# f28e12x_mem_cfg_regs register map
Vendor: Texas Instruments
Peripheral module from a debugger description file (folder C2000).
Address unit: 16 bits
Registers are 32-bit, read-write, no defined reset value unless marked. A register's access mark holds for its fields unless they carry their own. Offsets are as the file gives them; lines under a group give offsets from that group; [hi:lo] are bit positions; {n}, {i} and the like mark numbered series; 'fields as' and 'values as' point back to an identical list; <NAME> marks a mode.

## MEM_CFG_REGS — MEM CFG Registers
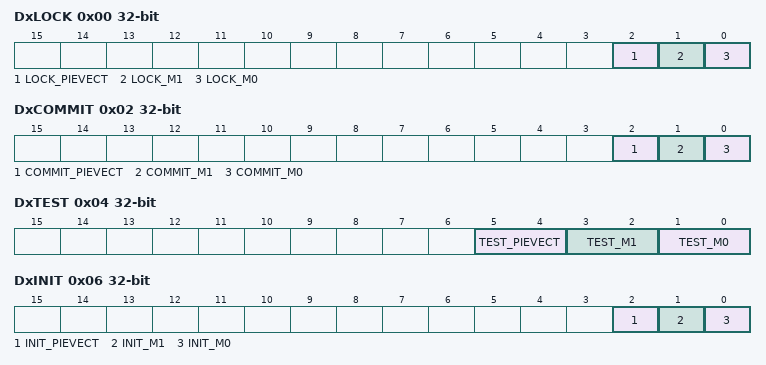
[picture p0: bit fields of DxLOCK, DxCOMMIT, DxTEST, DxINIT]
0x00 DxLOCK — Dedicated RAM config Lock Register
  [2] LOCK_PIEVECT — PIEVECT RAM Lock bits
  [1] LOCK_M1 — M1 RAM Lock bits
  [0] LOCK_M0 — M0 RAM Lock bits
0x02 DxCOMMIT — Dedicated RAM config Lock Commit Register
  [2] COMMIT_PIEVECT — PIEVECT RAM Permanent Lock bits
  [1] COMMIT_M1 — M1 RAM Permanent Lock bits
  [0] COMMIT_M0 — M0 RAM Permanent Lock bits
0x04 DxTEST — Dedicated RAM TEST Register
  [5:4] TEST_PIEVECT — Selects the different modes for PIEVECT RAM
  [3:2] TEST_M1 — Selects the different modes for M1 RAM
  [1:0] TEST_M0 — Selects the different modes for M0 RAM
0x06 DxINIT — Dedicated RAM Init Register
  [2] INIT_PIEVECT — RAM Initialization control for PIEVECT RAM.
  [1] INIT_M1 — RAM Initialization control for M1 RAM.
  [0] INIT_M0 — RAM Initialization control for M0 RAM.
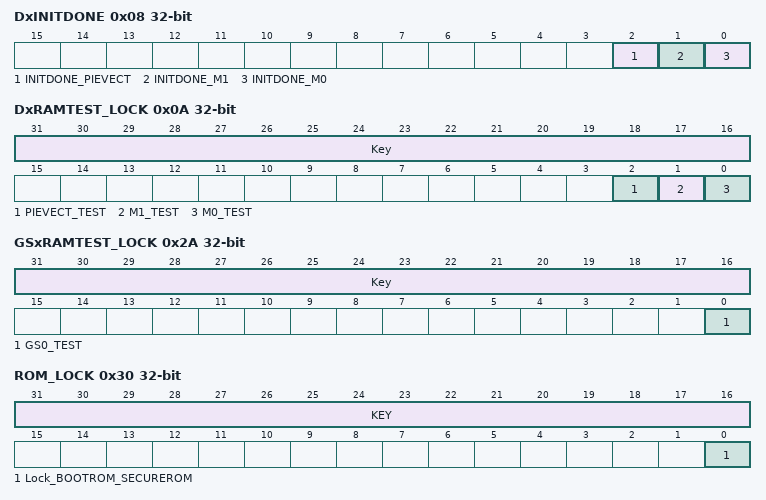
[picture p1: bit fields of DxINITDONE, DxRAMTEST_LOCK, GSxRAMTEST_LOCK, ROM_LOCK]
0x08 DxINITDONE ro — Dedicated RAM InitDone Status Register
  [2] INITDONE_PIEVECT — RAM Initialization status for PIEVECT RAM.
  [1] INITDONE_M1 — RAM Initialization status for M1 RAM.
  [0] INITDONE_M0 — RAM Initialization status for M0 RAM.
0x0A DxRAMTEST_LOCK — Dedicated RAM TEST Lock Register
  [31:16] Key — Key for writing DxRAMTEST lock
  [2] PIEVECT_TEST — PIEVECT_TEST_LOCK
  [1] M1_TEST — M1_TEST_LOCK
  [0] M0_TEST — M0_TEST_LOCK
0x20 GSxLOCK — Global Shared RAM Config Lock Register
  [0] LOCK_GS0 — GS0 RAM Lock bits
0x22 GSxCOMMIT — Global Shared RAM conffig Lock Commit Register
  [0] COMMIT_GS0 — GS0 RAM Permanent Lock bits
0x24 GSxTEST — Global Shared RAM TEST Register
  [1:0] TEST_GS0 — Selects the different modes for GS0 RAM
0x26 GSxINIT — Global Shared RAM Init Register
  [0] INIT_GS0 — RAM Initialization control for GS0 RAM.
0x28 GSxINITDONE ro — Global Shared RAM InitDone Status Register
  [0] INITDONE_GS0 — RAM Initialization status for GS0 RAM.
0x2A GSxRAMTEST_LOCK — Global Shared RAM TEST Lock Register
  [31:16] Key — Key for writing GSxRAMTEST lock
  [0] GS0_TEST — GS0_TEST_LOCK
0x30 ROM_LOCK — Rom configuration lock register
  [31:16] KEY — Key for writing ROM LOCK
  [0] Lock_BOOTROM_SECUREROM — BOOTROM and SECURE ROM lock bits
0x32 ROM_TEST
  [1:0] TEST_BOOTROM_SECUREROM — Selects the different modes for BOOTROM and SECURE ROM
0x34 ROM_FORCE_ERROR
  [0] FORCE_BOOTROM_SECUREROM_ERROR — Force Bootrom_SECUREROM Parity Error
